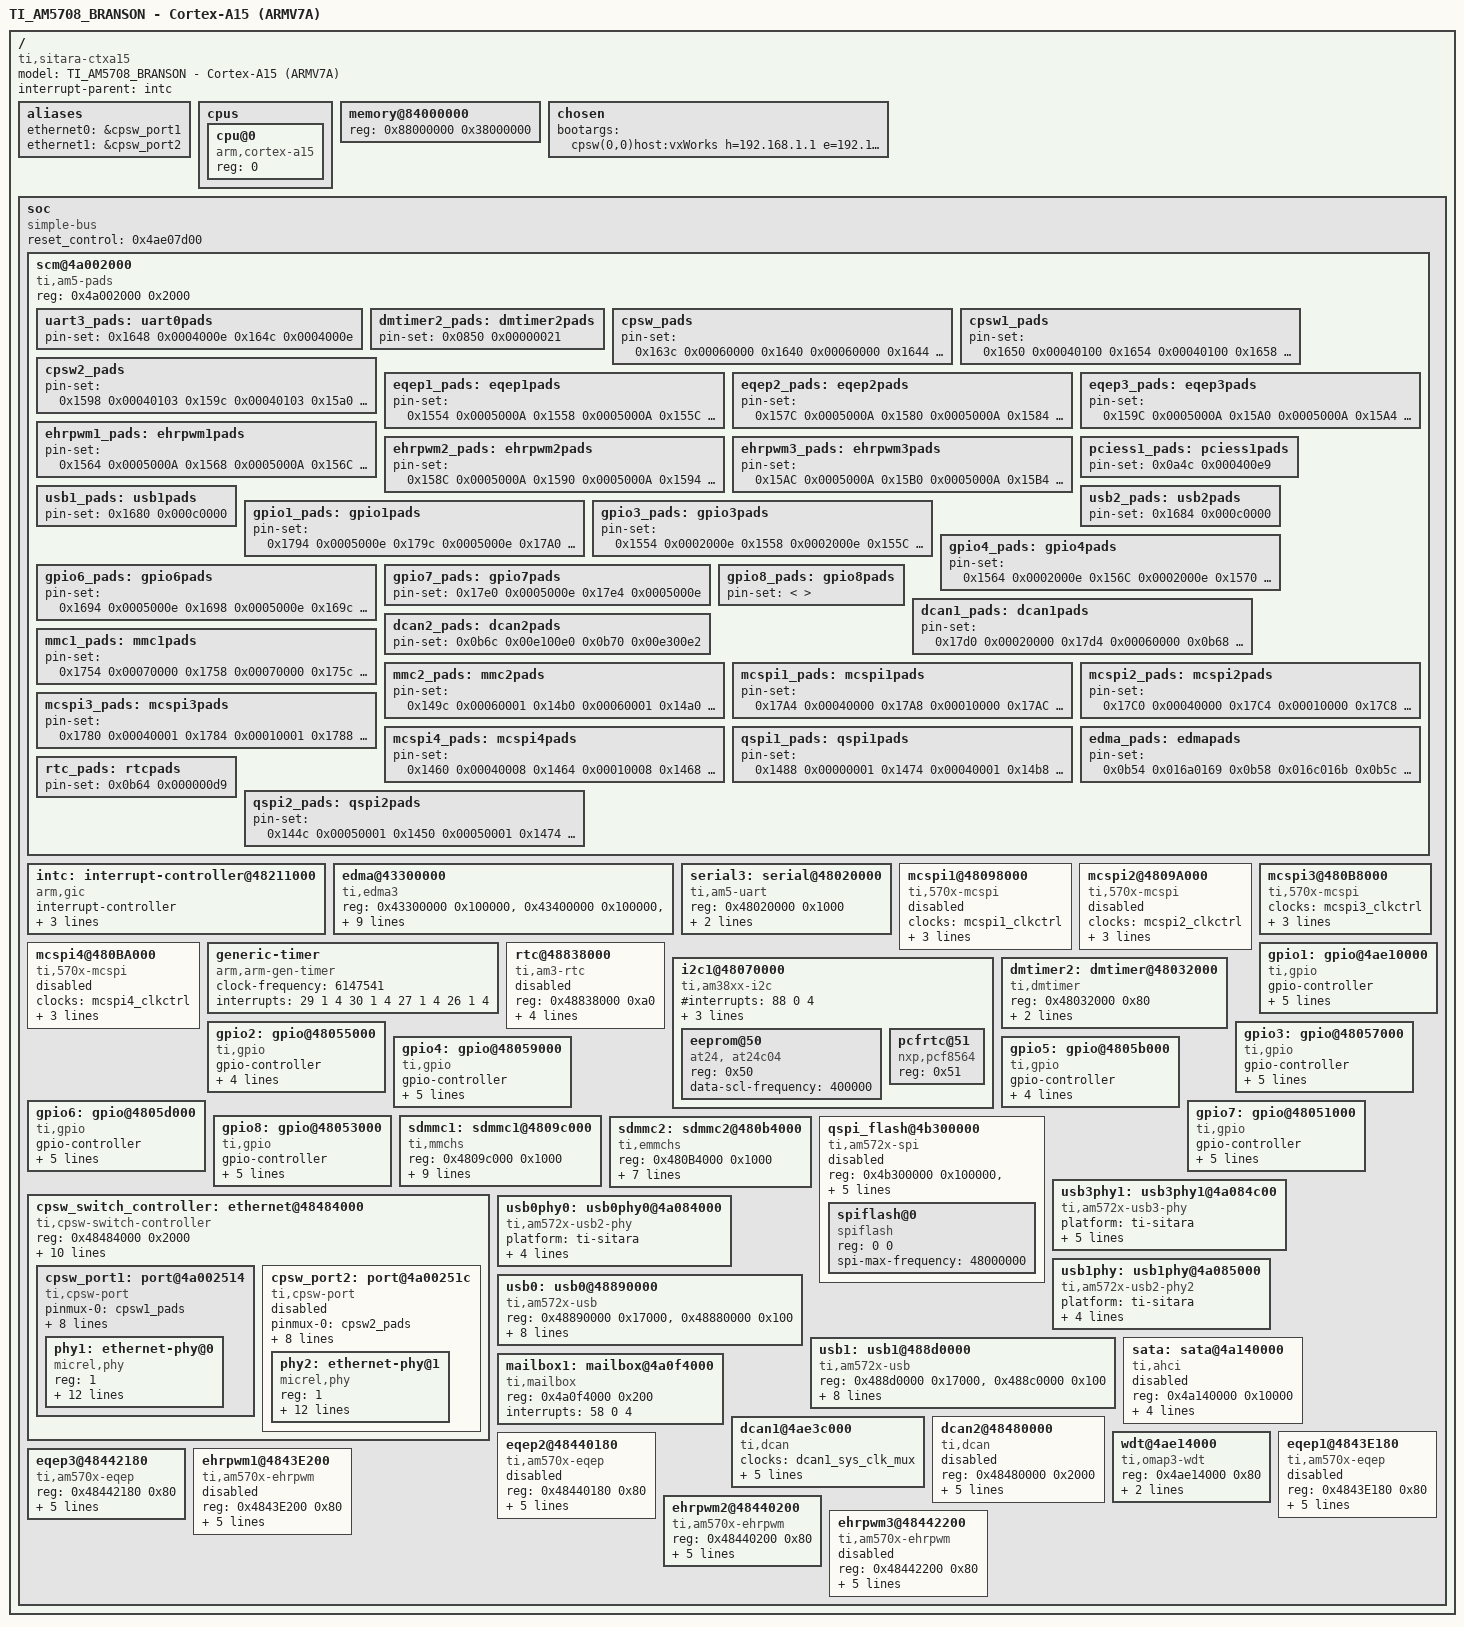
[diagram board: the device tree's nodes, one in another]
/* am5708_branson_ca15.dts - TI AM5708 Branson Board with Cortex-A15 device tree source */

/*
modification history
--------------------
20nov16,x_z  written
*/

#include "prjParams.h"

/dts-v1/;

/include/ "am572x_clock.dtsi"

/   {
    model = "TI_AM5708_BRANSON - Cortex-A15 (ARMV7A)";
    compatible = "ti,sitara-ctxa15";
    #address-cells = <1>;
    #size-cells = <1>;
    interrupt-parent = <&intc>;

    aliases
        {
        ethernet0 = &cpsw_port1;
        ethernet1 = &cpsw_port2;
        };

    cpus
        {
        #size-cells = <0>;
        #address-cells = <1>;

        cpu@0
            {
            device_type = "cpu";
            compatible = "arm,cortex-a15";
            reg = <0>;
            };
        };

    memory@84000000
        {
        device_type = "memory";
        reg = <0x88000000 0x38000000>;
        };

    chosen
        {
        bootargs = "cpsw(0,0)host:vxWorks h=192.168.1.1 e=192.168.1.100:ffffff00 u=target pw=vxTarget f=0x0";
        };

    soc
        {
        compatible = "simple-bus";
        device_type = "soc";
        #address-cells = <1>;
        #size-cells = <1>;
        reset_control = <0x4ae07d00>;                    /* PRM_RSTCTRL Register */
        ranges;

        /* control module */
        scm@4a002000
            {
            /* this device provide pads config */
            compatible = "ti,am5-pads";
            reg = <0x4a002000 0x2000>;

            uart3_pads: uart0pads
                {
                pin-set =
                    <
                    0x1648 0x0004000e                    /* CTRL_CORE_PAD_UART3_RXD rxd N5 */
                    0x164c 0x0004000e                    /* CTRL_CORE_PAD_UART3_TXD txd N6 */
                    >;
                    };

            dmtimer2_pads: dmtimer2pads
                {
                pin-set =
                    <
                    0x0850 0x00000021
                    >;
                };
            cpsw_pads: cpsw_pads
                {
                pin-set =
                    <
                    0x163c 0x00060000                    /* CTRL_CORE_PAD_MDIO_MCLK L5 */
                    0x1640 0x00060000                    /* CTRL_CORE_PAD_MDIO_D L6 */
                    0x1644 0x0004000d                    /* CTRL_CORE_PAD_RMII_MHZ_50_CLK */
                    0x0b20 0x014f014e                    /* CTRL_CORE_MPU_IRQ_114_115 IRQ_CROSSBAR_334 IRQ_CROSSBAR_335 */
                    0x0b24 0x01510150                    /* CTRL_CORE_MPU_IRQ_116_117 IRQ_CROSSBAR_336 IRQ_CROSSBAR_337 */
                    >;
                };
            cpsw1_pads: cpsw1_pads
                {
                pin-set =
                    <
                    0x1650 0x00040100                    /* CTRL_CORE_PAD_RGMII0_TXC */
                    0x1654 0x00040100                    /* CTRL_CORE_PAD_RGMII0_TXCTL */
                    0x1658 0x00040100                    /* CTRL_CORE_PAD_RGMII0_TXD3 */
                    0x165c 0x00040100                    /* CTRL_CORE_PAD_RGMII0_TXD2 */
                    0x1660 0x00040100                    /* CTRL_CORE_PAD_RGMII0_TXD1 */
                    0x1664 0x00040100                    /* CTRL_CORE_PAD_RGMII0_TXD0 */
                    0x1668 0x00040100                    /* CTRL_CORE_PAD_RGMII0_RXC */
                    0x166c 0x00040100                    /* CTRL_CORE_PAD_RGMII0_RXCTL */
                    0x1670 0x00060100                    /* CTRL_CORE_PAD_RGMII0_RXD3 */
                    0x1674 0x00060100                    /* CTRL_CORE_PAD_RGMII0_RXD2 */
                    0x1678 0x00060100                    /* CTRL_CORE_PAD_RGMII0_RXD1 */
                    0x167c 0x00060100                    /* CTRL_CORE_PAD_RGMII0_RXD0 */
                    >;
                };
            cpsw2_pads: cpsw2_pads
                {
                pin-set =
                    <
                    0x1598 0x00040103                    /* CTRL_CORE_PAD_VIN2A_D12  rgmii1_txc */
                    0x159c 0x00040103                    /* CTRL_CORE_PAD_VIN2A_D13  rgmii1_txctl */
                    0x15a0 0x00040103                    /* CTRL_CORE_PAD_VIN2A_D14  rgmii1_txd3 */
                    0x15a4 0x00040103                    /* CTRL_CORE_PAD_VIN2A_D15  rgmii1_txd2 */
                    0x15a8 0x00040103                    /* CTRL_CORE_PAD_VIN2A_D16  rgmii1_txd1 */
                    0x15ac 0x00040103                    /* CTRL_CORE_PAD_VIN2A_D17  rgmii1_txd0 */
                    0x15b0 0x00040103                    /* CTRL_CORE_PAD_VIN2A_D18  rgmii1_txd */
                    0x15b4 0x00040103                    /* CTRL_CORE_PAD_VIN2A_D19  rgmii1_rxctl */
                    0x15b8 0x00060103                    /* CTRL_CORE_PAD_VIN2A_D20  rgmii1_rxd3 */
                    0x15bc 0x00060103                    /* CTRL_CORE_PAD_VIN2A_D21  rgmii1_rxd2 */
                    0x15c0 0x00060103                    /* CTRL_CORE_PAD_VIN2A_D22  rgmii1_rxd1 */
                    0x15c4 0x00060103                    /* CTRL_CORE_PAD_VIN2A_D23  rgmii1_rxd0 */
                    >;
                };
            eqep1_pads: eqep1pads
                {
                pin-set =
                    <
                    0x1554 0x0005000A                    /* CTRL_CORE_PAD_VIN2A_CLK0   (D8) eQEP1A_in */
                    0x1558 0x0005000A                    /* CTRL_CORE_PAD_VIN2A_DE0    (B7) eQEP1B_in */
                    0x155C 0x0005000A                    /* CTRL_CORE_PAD_VIN2A_FLD0   (C7) eQEP1_index*/
                 /* 0x1560 0x0005000A */                 /* CTRL_CORE_PAD_VIN2A_HSYNC0 (E8) eQEP1_strobe */
                    0x0AA0 0x00CF00D2                    /* CTRL_CORE_MPU_IRQ_50_51: IRQ_CROSSBAR_207(0xCF) IRQ_CROSSBAR_210(0xD2) */
                    >;
                };
            eqep2_pads: eqep2pads
                {
                pin-set =
                    <
                    0x157C 0x0005000A                    /* CTRL_CORE_PAD_VIN2A_D5     (D8) eQEP2A_in */
                    0x1580 0x0005000A                    /* CTRL_CORE_PAD_VIN2A_D6     (B7) eQEP2B_in */
                    0x1584 0x0005000A                    /* CTRL_CORE_PAD_VIN2A_D7     (C7) eQEP2_index*/
                    0x1588 0x0005000A                    /* CTRL_CORE_PAD_VIN2A_D8     (E8) eQEP2_strobe */
                    0x0AA4 0x00D000D3                    /* CTRL_CORE_MPU_IRQ_52_53: IRQ_CROSSBAR_208(0xD0) IRQ_CROSSBAR_211(0xD3) */
                    >;
                };
            eqep3_pads: eqep3pads
                {
                pin-set =
                    <
                    0x159C 0x0005000A                    /* CTRL_CORE_PAD_VIN2A_D13   eQEP3A_in */
                    0x15A0 0x0005000A                    /* CTRL_CORE_PAD_VIN2A_D14   eQEP3B_in*/
                    0x15A4 0x0005000A                    /* CTRL_CORE_PAD_VIN2A_D15   eQEP3_index*/
                 /* 0x15A8 0x0005000A */                 /* CTRL_CORE_PAD_VIN2A_D16   eQEP3_strobe*/
                    0x0AC4 0x00D100D4                    /* CTRL_CORE_MPU_IRQ_68_69: IRQ_CROSSBAR_209(0xD1) IRQ_CROSSBAR_212(0xD4) */
                    >;
                };
            ehrpwm1_pads: ehrpwm1pads
                {
                pin-set =
                    <
                    0x1564 0x0005000A                    /* CTRL_CORE_PAD_VIN2A_VSYNC0    ehrpwm1A */
                    0x1568 0x0005000A                    /* CTRL_CORE_PAD_VIN2A_D0        ehrpwm1B */
                    0x156C 0x0005000A                    /* CTRL_CORE_PAD_VIN2A_D1        ehrpwm1_tripzone_input*/
                    0x1574 0x0005000A                    /* CTRL_CORE_PAD_VIN2A_D3        ehrpwm1_synci */
                    0x1578 0x0005000A                    /* CTRL_CORE_PAD_VIN2A_D4        ehrpwm1_synco */
                    0x0AA0 0x00CF00D2                    /* CTRL_CORE_MPU_IRQ_50_51: IRQ_CROSSBAR_207(0xCF) IRQ_CROSSBAR_210(0xD2) */
                    >;
                };
            ehrpwm2_pads: ehrpwm2pads
                {
                pin-set =
                    <
                    0x158C 0x0005000A                    /* CTRL_CORE_PAD_VIN2A_D9        ehrpwm2A */
                    0x1590 0x0005000A                    /* CTRL_CORE_PAD_VIN2A_D10       ehrpwm2B */
                    0x1594 0x0005000A                    /* CTRL_CORE_PAD_VIN2A_D11       ehrpwm2_tripzone_input*/
                    0x0AA4 0x00D000D3                    /* CTRL_CORE_MPU_IRQ_52_53: IRQ_CROSSBAR_208(0xD0) IRQ_CROSSBAR_211(0xD3) */
                    >;
                };
            ehrpwm3_pads: ehrpwm3pads
                {
                pin-set =
                    <
                    0x15AC 0x0005000A                    /* CTRL_CORE_PAD_VIN2A_D17       ehrpwm3A */
                    0x15B0 0x0005000A                    /* CTRL_CORE_PAD_VIN2A_D18       ehrpwm3B */
                    0x15B4 0x0005000A                    /* CTRL_CORE_PAD_VIN2A_D19       ehrpwm3_tripzone_input*/
                    0x0AC4 0x00D100D4                    /* CTRL_CORE_MPU_IRQ_68_69: IRQ_CROSSBAR_209(0xD1) IRQ_CROSSBAR_212(0xD4) */
                    >;
                };
            pciess1_pads: pciess1pads
                {
                pin-set =
                    <
                    0x0a4c 0x000400e9                    /* MPU_IRQ_40 */
                    >;
                };

            usb1_pads: usb1pads  
                {
                pin-set =
                    <
                    0x1680 0x000c0000                    /* usb1_drvvbus */
                    >;
                };

            usb2_pads: usb2pads  
                {
                pin-set =
                    <
                    0x1684 0x000c0000                    /* usb2_drvvbus */
                    >;
                };

            gpio1_pads: gpio1pads
                {
                pin-set =
                    <
                    0x1794 0x0005000e                    /* CTRL_CORE_PAD_MMC3_DAT4   GPIO1_22, Y3 GPIO: I-IN3 */
                    0x179c 0x0005000e                    /* CTRL_CORE_PAD_MMC3_DAT6   GPIO1_24, AA4 GPIO: I-IN0 */
                    0x17A0 0x0005000e                    /* CTRL_CORE_PAD_MMC3_DAT7   GPIO1_25, AB1 GPIO: I-OPSIG */
                    >;
                };

            gpio3_pads: gpio3pads
                {
                pin-set =
                    <
                    0x1554 0x0002000e                    /* CTRL_CORE_PAD_VIN2A_CLK0   GPIO3_28, D8 GPIO: O-READY */
                    0x1558 0x0002000e                    /* CTRL_CORE_PAD_VIN2A_DE0    GPIO3_29, B7 GPIO: O-GATHER */
                    0x155C 0x0002000e                    /* CTRL_CORE_PAD_VIN2A_FLD0   GPIO3_30, C7 GPIO: O-ANVIL */
                    0x1560 0x0002000e                    /* CTRL_CORE_PAD_VIN2A_HSYNC0 GPIO3_31, E8 GPIO: O-SPARE */
                    >;
                };

            gpio4_pads: gpio4pads
                {
                pin-set =
                    <
                    0x1564 0x0002000e                    /* CTRL_CORE_PAD_VIN2A_VSYNC0 GPIO4_0, B8 GPIO: O-HORN */
                 /* 0x1568 0x0002000e */                 /* CTRL_CORE_PAD_VIN2A_D0     GPIO4_1, C8 GPIO: O-ALARM */
                    0x156C 0x0002000e                    /* CTRL_CORE_PAD_VIN2A_D1     GPIO4_2, B9 GPIO:    O-OUT0 */
                    0x1570 0x0002000e                    /* CTRL_CORE_PAD_VIN2A_D2     GPIO4_3, A7 GPIO:    O-SAFETY */
                    0x1574 0x0002000e                    /* CTRL_CORE_PAD_VIN2A_D3     GPIO4_4, A9 GPIO:    \RUN_PSI */
                    0x1578 0x0002000e                    /* CTRL_CORE_PAD_VIN2A_D4     GPIO4_5, A8 GPIO: O-COOLAIR */
                    0x157C 0x0002000e                    /* CTRL_CORE_PAD_VIN2A_D5     GPIO4_6, A11 GPIO: \EXT_SEEK+ PSI */
                    0x1580 0x0002000e                    /* CTRL_CORE_PAD_VIN2A_D6     GPIO4_7, F10 GPIO: O_SEEK */                               
                    0x1584 0x0002000e                    /* CTRL_CORE_PAD_VIN2A_D7     GPIO4_8, A10 GPIO: BUZZ */
                 /* 0x1588 0x0002000e */                 /* CTRL_CORE_PAD_VIN2A_D8     GPIO4_9, B10 GPIO: \O/L RST PSI */
                 /* 0x158C 0x0002000e */                 /* CTRL_CORE_PAD_VIN2A_D9     GPIO4_10, E10 GPIO: O-OUT1 */
                 /* 0x1590 0x0002000e */                 /* CTRL_CORE_PAD_VIN2A_D10    GPIO4_11, D10 GPIO: \TEST PSI */
                    0x1598 0x0002000e                    /* CTRL_CORE_PAD_VIN2A_D12    GPIO4_13, B11 GPIO: \O/L RST PSI */
                    0x15B0 0x0002000e                    /* CTRL_CORE_PAD_VIN2A_D18    GPIO4_26, E11 GPIO: O-OUT1 */
                    0x15B8 0x0002000e                    /* CTRL_CORE_PAD_VIN2A_D20    GPIO4_28, B13 GPIO: \TEST PSI */
                    0x15BC 0x0002000e                    /* CTRL_CORE_PAD_VIN2A_D21    GPIO4_29, E13 GPIO: TEST PIN */
                    0x15C0 0x0002000e                    /* CTRL_CORE_PAD_VIN2A_D22    GPIO4_30, C13 GPIO: O-ALARM */
                    >;
                };

            gpio6_pads: gpio6pads
                {
                pin-set =
                    <
                    0x1694 0x0005000e                    /* CTRL_CORE_PAD_XREF_CLK0    GPIO6_17, J25 GPIO: I-PB2 */
                    0x1698 0x0005000e                    /* CTRL_CORE_PAD_XREF_CLK1    GPIO6_18, J24 GPIO: I-PB1 */
                    0x169c 0x0005000e                    /* CTRL_CORE_PAD_XREF_CLK2    GPIO6_19, H24 GPIO: O/L PS OUT */
                    0x16a0 0x0005000e                    /* CTRL_CORE_PAD_XREF_CLK3    GPIO6_20, H25 GPIO: I-IN4 */
                    0x1774 0x0005000e                    /* CTRL_CORE_PAD_GPIO6_10     GPIO6_10, Y5 GPIO: I-IN2 */
                    0x1778 0x0005000e                    /* CTRL_CORE_PAD_GPIO6_11     GPIO6_11, Y6 GPIO: I-AIRMON */
                    0x177c 0x0005000e                    /* CTRL_CORE_PAD_MMC3_CLK     GPIO6_29, Y2 GPIO:  I-COVCLE */
                    >;
                };
            gpio7_pads: gpio7pads
                {
                pin-set =
                    <
                    0x17e0 0x0005000e                    /* CTRL_CORE_PAD_UART1_RXD    GPIO7_22, L25 GPIO: I-ESTOPNC */
                    0x17e4 0x0005000e                    /* CTRL_CORE_PAD_UART1_TXD    GPIO7_23, M25 GPIO: I-ESTOPNCR */
                    >;
                };

            gpio8_pads: gpio8pads
                {
                pin-set =
                    <
                    >;
                };

            dcan1_pads: dcan1pads
                {
                pin-set =
                    <
                    0x17d0 0x00020000                    /* CTRL_CORE_PAD_DCAN1_TX  DCAN1_TX  H22*/
                    0x17d4 0x00060000                    /* CTRL_CORE_PAD_DCAN1_RX  DCAN1_RX  H23*/
                    0x0b68 0x00df00de                    /* CTRL_CORE_MPU_IRQ_152_153: IRQ_CROSSBAR_223 IRQ_CROSSBAR_222 */
                    0x0b6c 0x00e100e0                    /* CTRL_CORE_MPU_IRQ_154_155: IRQ_CROSSBAR_225 IRQ_CROSSBAR_224 */
                    >;
                };

            dcan2_pads: dcan2pads
                {
                pin-set =
                    <
                    0x0b6c 0x00e100e0                    /* CTRL_CORE_MPU_IRQ_154_155: IRQ_CROSSBAR_225 IRQ_CROSSBAR_224 */
                    0x0b70 0x00e300e2                    /* CTRL_CORE_MPU_IRQ_156_157: IRQ_CROSSBAR_227 IRQ_CROSSBAR_226 */
                    >;
                };

            mmc1_pads: mmc1pads
                {
                pin-set =
                    <
                    0x1754 0x00070000                    /* CTRL_CORE_PAD_MMC1_CLK  mmc1_clk  */
                    0x1758 0x00070000                    /* CTRL_CORE_PAD_MMC1_CMD  mmc1_cmd  */
                    0x175c 0x00070000                    /* CTRL_CORE_PAD_MMC1_DAT0 mmc1_dat0 */
                    0x1760 0x00070000                    /* CTRL_CORE_PAD_MMC1_DAT1 mmc1_dat1 */
                    0x1764 0x00070000                    /* CTRL_CORE_PAD_MMC1_DAT2 mmc1_dat2 */
                    0x1768 0x00070000                    /* CTRL_CORE_PAD_MMC1_DAT3 mmc1_dat3 */
                    >;
                };

            mmc2_pads: mmc2pads
                {
                pin-set =
                    <
                 /* 0x1864 0x00010000 */                 /* CTRL_CORE_PAD_RSTOUTN   emmc RSTn confirmed with schematic there is not any RSTn signal */
                    0x149c 0x00060001                    /* CTRL_CORE_PAD_GPMC_A23  emmc_clk  */
                    0x14b0 0x00060001                    /* CTRL_CORE_PAD_GPMC_CS1  emmc_cmd  */
                    0x14a0 0x00060001                    /* CTRL_CORE_PAD_GPMC_A24  emmc_dat0 */
                    0x14a4 0x00060001                    /* CTRL_CORE_PAD_GPMC_A25  emmc_dat1 */
                    0x14a8 0x00060001                    /* CTRL_CORE_PAD_GPMC_A26  emmc_dat2 */
                    0x14ac 0x00060001                    /* CTRL_CORE_PAD_GPMC_A27  emmc_dat3 */
                    0x148c 0x00060001                    /* CTRL_CORE_PAD_GPMC_A19  emmc_dat4 */
                    0x1490 0x00060001                    /* CTRL_CORE_PAD_GPMC_A20  emmc_dat5 */
                    0x1494 0x00060001                    /* CTRL_CORE_PAD_GPMC_A21  emmc_dat6 */
                    0x1498 0x00060001                    /* CTRL_CORE_PAD_GPMC_A22  emmc_dat7 */
                    >;
                };

            mcspi1_pads: mcspi1pads
                {
                pin-set =
                    <
                    0x17A4 0x00040000                    /* CTRL_CORE_PAD_SPI1_SCLK ( PIN_INPUT | MUX_MODE0 )  (C24) spi1_sclk.spi1_sclk */
                    0x17A8 0x00010000                    /* CTRL_CORE_PAD_SPI1_D1   ( PIN_OUTPUT | MUX_MODE0 )  (D24) spi1_d1.spi1_d1 MOSI*/
                    0x17AC 0x00050000                    /* CTRL_CORE_PAD_SPI1_D0   ( PIN_INPUT | MUX_MODE0 )  (D25) spi1_d0.spi1_d0 MISO */
                    0x17B0 0x00010000                    /* CTRL_CORE_PAD_SPI1_CS0  ( PIN_OUTPUT | MUX_MODE0 )  (B24) spi1_cs0.spi1_cs0 */
                    0x0b44 0x003d003c                    /* CTRL_CORE_MPU_IRQ_134_135: IRQ_CROSSBAR_61 IRQ_CROSSBAR_60 */
                    >;
                };

            mcspi2_pads: mcspi2pads
                {
                pin-set =
                    <
                    0x17C0 0x00040000                    /* CTRL_CORE_PAD_SPI2_SCLK ( PIN_INPUT | MUX_MODE0 )  (G25)  spi2_sclk */
                    0x17C4 0x00010000                    /* CTRL_CORE_PAD_SPI2_D1   ( PIN_OUTPUT | MUX_MODE0 )  (F25) spi2_d1 MOSI*/
                    0x17C8 0x00050000                    /* CTRL_CORE_PAD_SPI2_D0   ( PIN_INPUT | MUX_MODE0 )  (G24)  spi2_d0 MISO */
                    0x17CC 0x00010000                    /* CTRL_CORE_PAD_SPI2_CS0  ( PIN_OUTPUT | MUX_MODE0 )  (F24) spi2_cs0 */
                    0x17B4 0x00010003                    /* CTRL_CORE_PAD_SPI1_CS1  ( PIN_OUTPUT | MUX_MODE0 )  (C25) spi2_cs1 */
                    0x0b44 0x003d003c                    /* CTRL_CORE_MPU_IRQ_134_135: IRQ_CROSSBAR_61 IRQ_CROSSBAR_60 */
                    >;
                };
            mcspi3_pads: mcspi3pads
                {
                pin-set =
                    <
                    0x1780 0x00040001                    /* CTRL_CORE_PAD_MMC3_CMD  ( PIN_INPUT | MUX_MODE0 ) (Y1) spi3_sclk */
                    0x1784 0x00010001                    /* CTRL_CORE_PAD_MMC3_DAT0 ( PIN_OUTPUT | MUX_MODE0 ) (Y4) spi3_d1_MOSI */
                    0x1788 0x00050001                    /* CTRL_CORE_PAD_MMC3_DAT1 ( PIN_INPUT | MUX_MODE0 ) (AA2) spi3_d0_MISO */
                    0x178C 0x00010001                    /* CTRL_CORE_PAD_MMC3_DAT2 ( PIN_OUTPUT | MUX_MODE0 ) (AA3) spi3_cs0 */
                    0x1790 0x00010001                    /* CTRL_CORE_PAD_MMC3_DAT3 ( PIN_OUTPUT | MUX_MODE0 ) (W2) spi3_cs1 */
                    0x0b48 0x002b0056                    /* CTRL_CORE_MPU_IRQ_136_137: IRQ_CROSSBAR_43 IRQ_CROSSBAR_86 */
                    >;
                };

            mcspi4_pads: mcspi4pads
                {
                pin-set =
                    <
                    0x1460 0x00040008                    /* CTRL_CORE_PAD_GPMC_A8   ( PIN_INPUT | MUX_MODE0 )  (K4)  spi4_sclk TRM-P4680*/
                    0x1464 0x00010008                    /* CTRL_CORE_PAD_GPMC_A9   ( PIN_OUTPUT | MUX_MODE0 ) (H1)  spi4_d1 MOSI*/
                    0x1468 0x00050008                    /* CTRL_CORE_PAD_GPMC_A10  ( PIN_INPUT | MUX_MODE0 )  (J2)  spi4_d0 MISO */
                    0x146C 0x00010008                    /* CTRL_CORE_PAD_GPMC_A11  ( PIN_OUTPUT | MUX_MODE0 ) (L3)  spi4_cs0 */
                    0x1470 0x00010008                    /* CTRL_CORE_PAD_GPMC_A12  ( PIN_OUTPUT | MUX_MODE0 ) (G1)  spi4_cs1 */
                    0x0b48 0x002b0056                    /* CTRL_CORE_MPU_IRQ_136_137: IRQ_CROSSBAR_43 IRQ_CROSSBAR_86 */
                    >;
                };

            qspi1_pads: qspi1pads
                {
                pin-set =
                    <
                    0x1488 0x00000001                    /* CTRL_CORE_PAD_GPMC_A18  ( PIN_OUTPUT | MUX_MODE1 ) (F2) gpmc_a18.qspi1_sclk  */
                    0x1474 0x00040001                    /* CTRL_CORE_PAD_GPMC_A13  ( PIN_INPUT  | MUX_MODE1 ) (H3) gpmc_a13.qspi1_rtclk */
                    0x14b8 0x00000001                    /* CTRL_CORE_PAD_GPMC_CS2  ( PIN_OUTPUT  | PULL_DOWN | MUX_MODE1 ) (G4) gpmc_cs2.qspi1_cs0 */
                    0x1480 0x00040001                    /* CTRL_CORE_PAD_GPMC_A16  ( PIN_INPUT_OUTPUT | MUX_MODE1 ) (K5) gpmc_a16.qspi1_d0*/
                    0x1484 0x00040001                    /* CTRL_CORE_PAD_GPMC_A17  ( PIN_INPUT  | PULL_UP |  MUX_MODE1 ) (G2) gpmc_a17.qspi1_d1*/
                    0x147C 0x00060001                    /* CTRL_CORE_PAD_GPMC_A15  ( PIN_INPUT  | MUX_MODE1 ) (K6) gpmc_15.qspi1_d2*/
                    0x1478 0x00040001                    /* CTRL_CORE_PAD_GPMC_A14  ( PIN_INPUT  | MUX_MODE7 ) (H4) gpmc_a14.qspi1_d3 */
                    >;
                };

            edma_pads: edmapads
                {
                pin-set =
                    <
                    0x0b54 0x016a0169                    /* CTRL_CORE_MPU_IRQ_142_143: IRQ_CROSSBAR_361 IRQ_CROSSBAR_362 */
                    0x0b58 0x016c016b                    /* CTRL_CORE_MPU_IRQ_144_145: IRQ_CROSSBAR_363 IRQ_CROSSBAR_364 */
                    0x0b5c 0x016e016d                    /* CTRL_CORE_MPU_IRQ_146_147: IRQ_CROSSBAR_365 IRQ_CROSSBAR_366 */
                    0x0b60 0x0170016f                    /* CTRL_CORE_MPU_IRQ_148_149: IRQ_CROSSBAR_367 IRQ_CROSSBAR_368 */
                    >;
                };

            rtc_pads: rtcpads
                {
                pin-set =
                    <
                    0x0b64 0x000000d9                    /* CTRL_CORE_MPU_IRQ_150: IRQ_CROSSBAR_217 */
                    >; 
                }; 

            qspi2_pads: qspi2pads
                {
                pin-set =
                    <
                    0x144c 0x00050001                    /* spi1_cs2 */
                    0x1450 0x00050001                    /* spi1_cs3 */
                    0x1474 0x00050001                    /* qspi1_rtclk */
                    0x1478 0x00050001                    /* qspi1_d3 */
                    0x147c 0x00050001                    /* qspi1_d2 */
                    0x1480 0x00050001                    /* qspi1_d1 */
                    0x1484 0x00050001                    /* qspi1_d0 */
                    0x1488 0x00050001                    /* qspi1_sclk */
                    0x14b8 0x00060001                    /* qspi1_cs0 */
                    0x14bc 0x00060001                    /* qspi1_cs1 */
                    >; 
                }; 
            };

        intc: interrupt-controller@48211000
            {
            compatible = "arm,gic";
            #interrupt-cells = <3>;
            interrupt-controller;
            reg = <0x48211000 0x00001000>,               /* MPU Interrupt Controller Interfaces */
                  <0x48212000 0x00001000>;               /* MPU Interrupt Distributor */
            max-int-lvl = <480>;
            };

        edma@43300000
            {
            reg = <0x43300000 0x100000>,                 /* EDMA_TPCC */
                  <0x43400000 0x100000>,                 /* EDMA_TC0  */
                  <0x43500000 0x100000>;                 /* EDMA_TC1  */
            interrupt-parent = <&intc>;
            interrupts =
                <
                174 0 4
                175 0 4
                176 0 4
                177 0 4
                178 0 4
                179 0 4
                180 0 4
                181 0 4
                >;
            compatible      = "ti,edma3";
            #dma-cells      = <1>;
            dma-channels    = <64>;
            ti,edma-regions = <4>;
            ti,edma-slots   = <256>;
            clocks          = <&edma_ttcp1>, <&edma_ttcp2>;
            clock-names     = "edma_ttcp1","edma_ttcp2";
            pinmux-0        = <&edma_pads>;
            };

        serial3: serial@48020000
            {
            compatible  = "ti,am5-uart";
            reg         = <0x48020000 0x1000>;
            interrupts  = <106 0 4>;
            clocks      = <&uart3_gfclk_mux>;
            clock-names = "uart3_gfclk_mux";
            };

        mcspi1@48098000
            {
            #address-cells = <1>;
            #size-cells = <0>;
            compatible = "ti,570x-mcspi";
            clocks = <&mcspi1_clkctrl>;
            reg = <0x48098000 0x1000>;
            pinmux-0 = <&mcspi1_pads>;
            interrupts = <166 0 4>;                      /* MPU_IRQ_134 ID166 */
            status = "disabled";
            };

        mcspi2@4809A000
            {
            #address-cells = <1>;
            #size-cells = <0>;
            compatible = "ti,570x-mcspi";
            clocks = <&mcspi2_clkctrl>;
            reg = <0x4809A000 0x1000>;
            pinmux-0 = <&mcspi2_pads>;
            interrupts = <167 0 4>;                      /* MPU_IRQ_135 ID167 */
            status = "disabled";
            };

        mcspi3@480B8000
            {
            #address-cells = <1>;
            #size-cells = <0>;
            compatible = "ti,570x-mcspi";
            clocks = <&mcspi3_clkctrl>;
            reg = <0x480B8000 0x1000>;
            pinmux-0 = <&mcspi3_pads>;
            interrupts = <168 0 4>;                      /* MPU_IRQ_136 ID168 */
            };

        mcspi4@480BA000
            {
            #address-cells = <1>;
            #size-cells = <0>;
            compatible = "ti,570x-mcspi";
            clocks = <&mcspi4_clkctrl>;
            reg = <0x480BA000 0x1000>;
            pinmux-0 = <&mcspi4_pads>;
            interrupts = <169 0 4>;                      /* MPU_IRQ_136 ID168 */
            status = "disabled";
            };

        generic-timer
            {
            compatible = "arm,arm-gen-timer";
            clock-frequency = <6147541>;
            interrupts =
                <
                29 1 4                                   /* secure physical timer PPI */
                30 1 4                                   /* non-secure physical timer PPI */
                27 1 4                                   /* virtual timer PPI */
                26 1 4
                >;                                       /* hypervisor timer PPI */
            };

        rtc@48838000
            {
            compatible       = "ti,am3-rtc";
            reg              = <0x48838000 0xa0>;
            clocks           = <&rtcss_clk>;
            clock-names      = "rtcss_clk";
            pinmux-0         = <&rtc_pads>;
            interrupt-parent = <&intc>;
            interrupts       = <182 0 4>;
            status           = "disabled";
            };

        i2c1@48070000
            {
            compatible             = "ti,am38xx-i2c";
            #interrupts            = <88 0 4>;
            reg                    = <0x48070000 0xd6>;
            clocks                 = <&l4per_i2c1_mod>;
            clock-names            = "l4per_i2c1_mod";
            clock-frequency        = <400000>;
            #address-cells         = <1>;
            #size-cells            = <0>;

            eeprom@50
                {
                compatible         = "at24, at24c04";
                reg                = <0x50>;
                data-scl-frequency = <400000>;
                };

            pcfrtc@51
                {
                compatible         = "nxp,pcf8564";
                reg                = <0x51>;
                };
            };

        dmtimer2: dmtimer@48032000
            {
            compatible      = "ti,dmtimer";
            #address-cells  = <1>;
            #size-cells     = <1>;
            reg             = <0x48032000 0x80>;
            clocks          = <&timer2_gfclk_mux>;
            clock-names     = "timer2_gfclk_mux";
            interrupts      = <70 0 4>;
            };

        gpio1: gpio@4ae10000
            {
            compatible      = "ti,gpio";
            gpio-controller;
            #gpio-cells     = <4>;
            #interrupt-cells= <1>;
            bankid          = <0>;
            reg             = <0x4ae10000 0x200>;
            interrupts      = <61 0 4>;
            pinmux-0        = <&gpio1_pads>;
            clocks          = <&gpio1_dbclk>;
            clock-names     = "gpio1_dbclk";
            };

        gpio2: gpio@48055000
            {
            compatible      = "ti,gpio";
            gpio-controller;
            #gpio-cells     = <4>;
            #interrupt-cells= <1>;
            bankid          = <1>;
            reg             = <0x48055000 0x200>;
            interrupts      = <62 0 4>;
            clocks          = <&gpio2_dbclk>;
            clock-names     = "gpio2_dbclk";
            };

        gpio3: gpio@48057000
            {
            compatible      = "ti,gpio";
            gpio-controller;
            #gpio-cells     = <4>;
            #interrupt-cells= <1>;
            bankid          = <2>;
            reg             = <0x48057000 0x200>;
            interrupts      = <63 0 4>;
            pinmux-0        = <&gpio3_pads>;             /* conflicted with eqep1 */
            clocks          = <&gpio3_dbclk>;
            clock-names     = "gpio3_dbclk";
            };

        gpio4: gpio@48059000
            {
            compatible      = "ti,gpio";
            gpio-controller;
            #gpio-cells     = <4>;
            #interrupt-cells= <1>;
            bankid          = <3>;
            reg             = <0x48059000 0x200>;
            interrupts      = <64 0 4>;
            pinmux-0        = <&gpio4_pads>;             /* conflicted with eqep2 & ehrpwm1 & ehrpwm2 & ehrpwm3 */
            clocks          = <&gpio4_dbclk>;
            clock-names     = "gpio4_dbclk";
            };

        gpio5: gpio@4805b000
            {
            compatible      = "ti,gpio";
            gpio-controller;
            #gpio-cells     = <4>;
            #interrupt-cells= <1>;
            bankid          = <4>;
            reg             = <0x4805b000 0x200>;
            interrupts      = <65 0 4>;
            clocks          = <&gpio5_dbclk>;
            clock-names     = "gpio5_dbclk";
            };

        gpio6: gpio@4805d000
            {
            compatible      = "ti,gpio";
            gpio-controller;
            #gpio-cells     = <4>;
            #interrupt-cells= <1>;
            bankid          = <5>;
            reg             = <0x4805d000 0x200>;
            interrupts      = <66 0 4>;
            pinmux-0        = <&gpio6_pads>;
            clocks          = <&gpio6_dbclk>;
            clock-names     = "gpio6_dbclk";
            };

        gpio7: gpio@48051000
            {
            compatible      = "ti,gpio";
            gpio-controller;
            #gpio-cells     = <4>;
            #interrupt-cells= <1>;
            bankid          = <6>;
            reg             = <0x48051000 0x200>;
            interrupts      = <67 0 4>;
            pinmux-0        = <&gpio7_pads>;
            clocks          = <&gpio7_dbclk>;
            clock-names     = "gpio7_dbclk";
            };

        gpio8: gpio@48053000
            {
            compatible      = "ti,gpio";
            gpio-controller;
            #gpio-cells     = <4>;
            #interrupt-cells= <1>;
            bankid          = <7>;
            reg             = <0x48053000 0x200>;
            interrupts      = <153 0 4>;
            pinmux-0        = <&gpio8_pads>;
            clocks          = <&gpio8_dbclk>;
            clock-names     = "gpio8_dbclk";
            };

        sdmmc1: sdmmc1@4809c000
            {
            compatible      = "ti,mmchs";
            reg             = <0x4809c000 0x1000>;
            interrupts      = <115 0 4>;
            pinmux-0        = <&mmc1_pads>;
            clocks          = <&mmc1_fclk_div>;
            clock-names     = "mmc1_fclk_div";
            dma-mode        = <0>;
            dma-rxevt       = <61>;
            dma-txevt       = <60>;
            cd-gpios        = <&gpio6 27 0 0 0>;
            debounce-time   = <7936>;
            userUhsMode     = <1>;
            };

        sdmmc2: sdmmc2@480b4000
            {
            compatible      = "ti,emmchs";
            reg             = <0x480B4000 0x1000>;
            interrupts      = <118 0 4>;
            pinmux-0        = <&mmc2_pads>;
            clocks          = <&mmc2_fclk_div>;
            clock-names     = "mmc2_fclk_div";
            dma-mode        = <0>;
            dma-rxevt       = <47>;
            dma-txevt       = <46>;
            debounce-time   = <7936>;
            };

        qspi_flash@4b300000
            {
            status                = "disabled";
            #address-cells        = <1>;
            #size-cells           = <1>;
            compatible            = "ti,am572x-spi";
            reg =
                <0x4b300000 0x100000>,
                <0x5c000000 0x4000000>,
                <0x4A002558 0x20>,
                <0x4A009838 0x20>;
            pinmux-0              = <&qspi1_pads>;
            clocks                = <&qspi_gfclk_div>;
            clock-frequency       = <48000000>;
            spiflash@0
                {
                #address-cells    = <1>;
                #size-cells       = <0>;
                compatible        = "spiflash";
                reg               = <0 0>;
                spi-max-frequency = <48000000>;
                };
            };

        cpsw_switch_controller: ethernet@48484000        /* ethernet system */
            {
            compatible = "ti,cpsw-switch-controller";    /* switch controller device */
            #address-cells = <1>;
            #size-cells    = <1>;

            reg = <0x48484000 0x2000>;                   /* CPSW register space */
            cpsw-port0-offset = <0x0108>;                /* offset - Ethernet Switch Port Control of port0 */
            cpsw-cpdma-offset = <0x0800>;                /* offset - CPPI DMA Controller Module */
            cpsw-hdp-offset   = <0x0a00>;                /* offset - HDP */
            cpsw-stats-offset = <0x0900>;                /* offset - Ethernet Statistics */
            cpsw-ale-offset   = <0x0d00>;                /* offset - Ethernet Address Lookup Engine */
            cpsw-mdio-offset  = <0x1000>;                /* offset - Ethernet MDIO Controller */
            cpsw-wr-offset    = <0x1200>;                /* offset - Ethernet Subsystem Wrapper for RMII/RGMII */

            clocks            = <&gmac_rft_clk_mux>, <&gmac_gmii_ref_clk_div>;
            clock-names       = "gmac_rft_clk_mux","gmac_gmii_ref_clk_div";
            pinmux-0          = <&cpsw_pads>;            /* pinmux setting */

            cpsw_port1: port@4a002514                    /* port device*/
                {
                #address-cells = <1>;
                #size-cells    = <0>;
                device_type    = "network";
                compatible     = "ti,cpsw-port";
                pinmux-0          = <&cpsw1_pads>;       /* pinmux setting */
                interrupts =
                    <147 0 4>,                           /* c0_rx_pend */
                    <148 0 4>,                           /* c0_tx_pend */
                    <149 0 4>;                           /* c0_misc_pend */
                cpsw-port-index  = <1>;
                cpsw-gmac-offset = <0xd80>;
                cpsw-port-offset = <0x208>;

                /*
                * The mac address will be fetched out from CTRL_MAC_ID with
                * higher priority than local-mac-address, each board has an
                * unique address for each mac port which was saved in
                * CTRL_MAC_ID, if this area was not supplied or it does not
                * exist, the mac address will be fetched out from
                * local-mac-address area. Please be careful to use
                * local-mac-address with more than one boards in same LAN, DO
                * NOT use the same local-mac-address value with each board for
                * it will lead ARP confict in same LAN.
                * When the CTRL_MAC_ID area and local-mac-address was supplied
                * simultaneously(here is an example), CTRL_MAC_ID win which
                * means mac address will be fetched out from CTRL_MAC_ID in
                * stead of local-mac-address.
                */

                cpsw-mac-save-way = <1>;
                reg =
                    <0x4a002514 0x4>,                    /* CTRL_MAC_ID0_LO */
                    <0x4a002518 0x4>;                    /* CTRL_MAC_ID0_HI */
                local-mac-address = [ 00 40 47 E0 A8 32 ];

                phy-handle = <&phy1>;                    /* port1 use phy1 */
                phy1: ethernet-phy@0                     /* phy of port0 */
                    {
                    #address-cells = <1>;
                    #size-cells    = <0>;
                    compatible     = "micrel,phy";
                    reg            = <1>;                /* phy address : 1 */
                    rxc-skew-ps    = <900>;              /* clock pad skew */
                    txc-skew-ps    = <900>;              /* clock pad skew */
                    txen-skew-ps   = <420>;
                    rxdv-skew-ps   = <420>;
                    rxd0-skew-ps   = <420>;
                    rxd1-skew-ps   = <420>;
                    rxd2-skew-ps   = <420>;
                    rxd3-skew-ps   = <420>;
                    txd0-skew-ps   = <420>;
                    txd1-skew-ps   = <420>;
                    txd2-skew-ps   = <420>;
                    txd3-skew-ps   = <420>;
                    };
                };

            cpsw_port2: port@4a00251c                    /* port device*/
                {
                status         = "disabled";
                #address-cells = <1>;
                #size-cells    = <0>;
                device_type    = "network";
                compatible     = "ti,cpsw-port";
                pinmux-0       = <&cpsw2_pads>;          /* conflicted with eqep3 & ehrpwm3 */
                interrupts =
                    <147 0 4>,                           /* c0_rx_pend */
                    <148 0 4>,                           /* c0_tx_pend */
                    <149 0 4>;                           /* c0_misc_pend */
                cpsw-port-index  = <2>;
                cpsw-gmac-offset = <0xdc0>;
                cpsw-port-offset = <0x308>;

                /*
                * The mac address will be fetched out from CTRL_MAC_ID with
                * higher priority than local-mac-address, each board has an
                * unique address for each mac port which was saved in
                * CTRL_MAC_ID, if this area was not supplied or it does not
                * exist, the mac address will be fetched out from
                * local-mac-address area. Please be careful to use
                * local-mac-address with more than one boards in same LAN, DO
                * NOT use the same local-mac-address value with each board for
                * it will lead ARP confict in same LAN.
                * When the CTRL_MAC_ID area and local-mac-address was supplied
                * simultaneously(here is an example), CTRL_MAC_ID win which
                * means mac address will be fetched out from CTRL_MAC_ID in
                * stead of local-mac-address.
                */

                cpsw-mac-save-way = <1>;
                reg =
                    <0x4a00251c 0x4>,                    /* CTRL_MAC_ID1_LO */
                    <0x4a002520 0x4>;                    /* CTRL_MAC_ID1_HI */
                local-mac-address = [ 00 40 47 E0 A8 33 ];

                phy-handle = <&phy2>;                    /* port2 use phy2 */
                phy2: ethernet-phy@1                     /* phy of port2 */
                    {
                    #address-cells = <1>;
                    #size-cells    = <0>;
                    compatible     = "micrel,phy";
                    reg            = <1>;                /* phy address : 1 */
                    rxc-skew-ps    = <900>;              /* clock pad skew */
                    txc-skew-ps    = <900>;              /* clock pad skew */
                    txen-skew-ps   = <420>;
                    rxdv-skew-ps   = <420>;
                    rxd0-skew-ps   = <420>;
                    rxd1-skew-ps   = <420>;
                    rxd2-skew-ps   = <420>;
                    rxd3-skew-ps   = <420>;
                    txd0-skew-ps   = <420>;
                    txd1-skew-ps   = <420>;
                    txd2-skew-ps   = <420>;
                    txd3-skew-ps   = <420>;
                    };
                };
            };

        usb3phy1: usb3phy1@4a084c00
            {
            compatible   = "ti,am572x-usb3-phy";
            platform     = "ti-sitara";
            reg          =
                <0x4a084c00 0x40>,
                <0x4a002370 0x04>,
                <0x4a080000 0x20>;
            phy_type     = "utmi";
            clocks       =
                <&usb_phy3_always_on_clk32k>,
                <&sys_clkin1>,
                <&ocp2scp1_mod>,
                <&usb_otg_ss1_refclk960m>;
            clock-names  =
                "usb_phy3_always_on_clk32k",
                "sys_clkin1",
                "ocp2scp1_mod",
                "usb_otg_ss1_refclk960m";
            };

        usb0phy0: usb0phy0@4a084000
            {
            compatible = "ti,am572x-usb2-phy";
            platform   = "ti-sitara";
            reg        =
                <0x4a084000 0x100>,
                <0x4a002300 0x04>;
            phy_type   = "utmi";
            clocks       =
                <&usb_phy1_always_on_clk32k>,
                <&usb_otg_ss1_refclk960m>;
            clock-names  =
                "usb_phy1_always_on_clk32k",
                "usb_otg_ss1_refclk960m";
            };

        usb1phy: usb1phy@4a085000
            {
            compatible = "ti,am572x-usb2-phy2";
            platform   = "ti-sitara";
            reg        =
                <0x4a085000 0x100>,
                <0x4a002e74 0x04>;
            phy_type   = "utmi";
            clocks     =
                <&usb_phy2_always_on_clk32k>,
                <&usb_otg_ss2_refclk960m>;
            clock-names=
                "usb_phy2_always_on_clk32k",
                "usb_otg_ss2_refclk960m";
            };

        usb0: usb0@48890000
            {
            compatible = "ti,am572x-usb";
            reg        =
                <0x48890000 0x17000>,
                <0x48880000 0x100>;
            interrupts = <108 0 4>;
            dr_mode    = "host";
            usbphy = <&usb0phy0>;
            pinmux-0   = <&usb1_pads>;
            clocks     =
                <&usb_phy1_always_on_clk32k>,
                <&usb_otg_ss1_refclk960m>,
                <&usb_phy3_always_on_clk32k>,
                <&sys_clkin1>,
                <&sys_clkin2>;
            clock-names=
                "usb_phy1_always_on_clk32k",
                "usb_otg_ss1_refclk960m", 
                "usb_phy3_always_on_clk32k",
                "sys_clkin1",
                "sys_clkin2";
            };

        usb1: usb1@488d0000
            {
            compatible = "ti,am572x-usb";
            reg        =
                <0x488d0000 0x17000>,
                <0x488c0000 0x100>;
            interrupts = <110 0 4>;
            dr_mode    = "host";
            usbphy = <&usb1phy>;
            pinmux-0   = <&usb2_pads>;
            clocks     =
                <&usb_phy2_always_on_clk32k>,
                <&usb_otg_ss2_refclk960m>,
                <&l3init_60m_fclk>,
                <&l3_iclk_div>,
                <&usb2_mod>,
                <&usb_otg_clkin_ck>,
                <&sys_clkin1>,
                <&sys_clkin2>;
            clock-names=
                "usb_phy2_always_on_clk32k",
                "usb_otg_ss2_refclk960m", 
                "l3init_60m_fclk",
                "l3_iclk_div",
                "usb2_mod",
                "usb_otg_clkin_ck",
                "sys_clkin1",
                "sys_clkin2";
            };

        sata: sata@4a140000
            {
            status     = "disabled";
            compatible = "ti,ahci";     
            reg        = <0x4a140000 0x10000>;
            interrupts = <86 0 4>;
            clocks     =
                <&sata_ref_clk>,
                <&l3_iclk_div>,
                <&func_48m_fclk>,
                <&sata_mod>;
            clock-names=
                "sata_ref_clk",
                "l3_iclk_div", 
                "func_48m_fclk",
                "sata_mod";
            /*
            *   Sometime there are more than one SATA controllers, such as
            *   sata controller on the chip, PCI-sata controller.. etc.
            *   If you want to disable that not used, 
            *   just set the disable-controller as the following:
            *   
            *   for example :  disable-controller = "1,2,3";
            *
            *   1 - PCI-AHCI,
            *   2 - FDT-AHCI,         for on-chip AHCI
            *   3 - SATA_CTRL_SI31xx, for Sillicon Imagic
            *   4 - SATA_CTRL_FSL,    for FreeScale
            *   5 - PCI-PIIX,         (IDE ctroller)
            *             
            */ 
            disable-controller = "1,3,4,5";
            };

        mailbox1: mailbox@4a0f4000
            {
            compatible = "ti,mailbox";
            reg = <0x4a0f4000 0x200>;
            interrupts = <58 0 4>;
            };
        dcan1@4ae3c000
            {
            compatible  = "ti,dcan";
            clocks      = <&dcan1_sys_clk_mux>;
            clock-names = "dcan1_sys_clk_mux";
            pinctrl-0   = <&dcan1_pads>;
            reg         = <0x4ae3c000 0x2000>;
            interrupts  = <184 0 4>, <185 0 4>, <186 0 4>;/* MPU_IRQ_152 (ID184) MPU_IRQ_153 (ID185) MPU_IRQ_154 (ID186) */
            interrupt-parent = <&intc>;
            /* bit-timing = <0x9 0x2 0x2 0x1 0x0>; */       /* 1M */
            bit-timing = <0xe 0x4 0x2 0x4 0x0>;       /* 500K */
            };
        dcan2@48480000
            {
            status      = "disabled";
            compatible  = "ti,dcan";
            reg         = <0x48480000 0x2000>;
            clocks      = <&dcan2_sys_clk_mux>;
            clock-names = "dcan2_sys_clk_mux";
            pinctrl-0   = <&dcan2_pads>;
            interrupts  = <187 0 4>, <188 0 4>, <189 0 4>;/* MPU_IRQ_155 (ID187) MPU_IRQ_156 (ID188) MPU_IRQ_157 (ID189)*/
            interrupt-parent = <&intc>;
            bit-timing  = <0x9 0x2 0x2 0x1 0x0>;
            };
        wdt@4ae14000
            {
            compatible = "ti,omap3-wdt";
            reg = <0x4ae14000 0x80>;
            timeout-sec = <20>;
            enable = <0>;                                /* 1 for enable, other for disable */
            };

        eqep1@4843E180
            {
            status      = "disabled";
            compatible  = "ti,am570x-eqep";
            reg         = <0x4843E180 0x80>;
            pinctrl-0   = <&eqep1_pads>;                 /* conflicted with gpio3 */
            clocks      = <&pwmss1_giclk_mux>;
            clock-names = "pwmss1_giclk_mux";
            interrupt-parent = <&intc>;
            interrupts  = <82 0 4>;                      /* MPU_IRQ_50 ID82 */
            pwmss       = <0x4843E000>;
            };
        eqep2@48440180
            {
            status      = "disabled";
            compatible  = "ti,am570x-eqep";
            reg         = <0x48440180 0x80>;
            pinctrl-0   = <&eqep2_pads>;                 /* conflicted with gpio4 */
            clocks      = <&pwmss2_giclk_mux>;
            clock-names = "pwmss2_giclk_mux";
            interrupt-parent = <&intc>;
            interrupts  = <84 0 4>;                      /* MPU_IRQ_52 ID84 */
            pwmss       = <0x48440000>;
            };
        eqep3@48442180
            {
            compatible  = "ti,am570x-eqep";
            reg         = <0x48442180 0x80>;
            pinctrl-0   = <&eqep3_pads>;                 /* conflicted with cpsw2 */
            clocks      = <&pwmss3_giclk_mux>;
            clock-names = "pwmss3_giclk_mux";
            interrupt-parent = <&intc>;
            interrupts  = <100 0 4>;                     /* MPU_IRQ_68 ID100 */
            pwmss       = <0x48442000>;
            };

        ehrpwm1@4843E200
            {
            status      = "disabled";
            compatible  = "ti,am570x-ehrpwm";
            reg         = <0x4843E200 0x80>;
            pinctrl-0   = <&ehrpwm1_pads>;               /* conflicted with gpio4 */
            clocks      = <&pwmss1_giclk_mux>;
            clock-names = "pwmss1_giclk_mux";
            interrupt-parent = <&intc>;
            interrupts  = <83 0 4>;                      /* MPU_IRQ_51 ID83 */
            pwmss       = <0x4843E000>;
            };
        ehrpwm2@48440200
            {
            compatible  = "ti,am570x-ehrpwm";
            reg         = <0x48440200 0x80>;
            pinctrl-0   = <&ehrpwm2_pads>;               /* conflicted with gpio4 */
            clocks      = <&pwmss2_giclk_mux>;
            clock-names = "pwmss2_giclk_mux";
            interrupt-parent = <&intc>;
            interrupts  = <85 0 4>;                      /* MPU_IRQ_53 ID85 */
            pwmss       = <0x48440000>;
            };
        ehrpwm3@48442200
            {
            status      = "disabled";
            compatible  = "ti,am570x-ehrpwm";
            reg         = <0x48442200 0x80>;
            pinctrl-0   = <&ehrpwm3_pads>;               /* conflicted with cpsw2 & gpio4 */
            clocks      = <&pwmss3_giclk_mux>;
            clock-names = "pwmss3_giclk_mux";
            interrupt-parent = <&intc>;
            interrupts  = <101 0 4>;                     /* MPU_IRQ_69 ID101 */
            pwmss       = <0x48442000>;
            };
        };/* end of soc */
    };/* end of root */

